# usb register map
Vendor: Texas Instruments
Peripheral module from a debugger description file (folder tm4c1232c3pm).
Registers are 8-bit, read-write, no defined reset value unless marked. A register's access mark holds for its fields unless they carry their own. Offsets are as the file gives them; lines under a group give offsets from that group; [hi:lo] are bit positions; {n}, {i} and the like mark numbered series; 'fields as' and 'values as' point back to an identical list; <NAME> marks a mode.

## USB0 — Univeral Serial Bus register offsets
0x00 USB_FADDR — USB Device Functional Address
  [6:0] USB_FADDR — Function Address
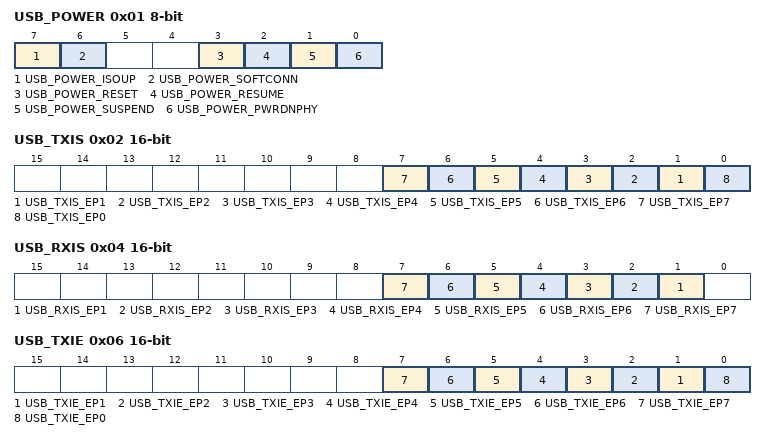
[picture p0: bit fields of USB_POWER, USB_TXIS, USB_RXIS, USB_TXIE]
0x01 USB_POWER
  [7] USB_POWER_ISOUP — Isochronous Update
  [6] USB_POWER_SOFTCONN — Soft Connect/Disconnect
  [3] USB_POWER_RESET — RESET Signaling
  [2] USB_POWER_RESUME — RESUME Signaling
  [1] USB_POWER_SUSPEND — SUSPEND Mode
  [0] USB_POWER_PWRDNPHY — Power Down PHY
0x02 USB_TXIS 16-bit ro — USB Transmit Interrupt Status
  [n] USB_TXIS_EP{n} (n=1..7) — TX Endpoint {n} Interrupt
  [0] USB_TXIS_EP0 — TX and RX Endpoint 0 Interrupt
0x04 USB_RXIS 16-bit ro — USB Receive Interrupt Status
  [n] USB_RXIS_EP{n} (n=1..7) — RX Endpoint {n} Interrupt
0x06 USB_TXIE 16-bit — USB Transmit Interrupt Enable
  [n] USB_TXIE_EP{n} (n=1..7) — TX Endpoint {n} Interrupt Enable
  [0] USB_TXIE_EP0 — TX and RX Endpoint 0 Interrupt Enable
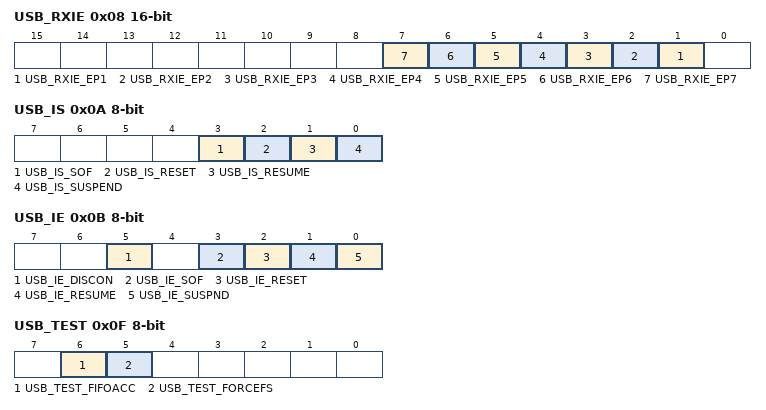
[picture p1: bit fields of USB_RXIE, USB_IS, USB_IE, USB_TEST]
0x08 USB_RXIE 16-bit — USB Receive Interrupt Enable
  [n] USB_RXIE_EP{n} (n=1..7) — RX Endpoint {n} Interrupt Enable
0x0A USB_IS ro — USB General Interrupt Status
  [3] USB_IS_SOF — Start of Frame
  [2] USB_IS_RESET — RESET Signaling Detected
  [1] USB_IS_RESUME — RESUME Signaling Detected
  [0] USB_IS_SUSPEND — SUSPEND Signaling Detected
0x0B USB_IE — USB Interrupt Enable
  [5] USB_IE_DISCON — Enable Disconnect Interrupt
  [3] USB_IE_SOF — Enable Start-of-Frame Interrupt
  [2] USB_IE_RESET — Enable RESET Interrupt
  [1] USB_IE_RESUME — Enable RESUME Interrupt
  [0] USB_IE_SUSPND — Enable SUSPEND Interrupt
0x0C USB_FRAME 16-bit ro — USB Frame Value
  [10:0] USB_FRAME — Frame Number
0x0E USB_EPIDX — USB Endpoint Index
  [3:0] USB_EPIDX_EPIDX — Endpoint Index
0x0F USB_TEST — USB Test Mode
  [6] USB_TEST_FIFOACC — FIFO Access
  [5] USB_TEST_FORCEFS — Force Full-Speed Mode
{0x20+4i} USB_FIFO{i} 32-bit (i=0..7) — USB FIFO Endpoint {i}
  [31:0] USB_FIFO{i}_EPDATA — Endpoint Data
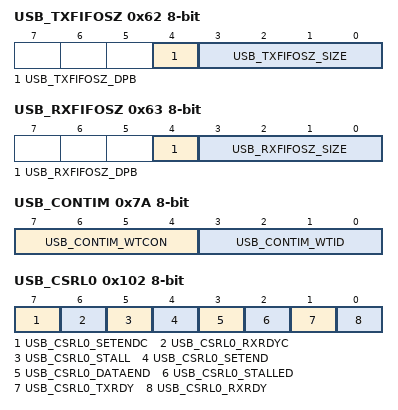
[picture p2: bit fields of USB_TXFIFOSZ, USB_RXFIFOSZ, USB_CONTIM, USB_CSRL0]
0x62 USB_TXFIFOSZ — USB Transmit Dynamic FIFO Sizing
  [4] USB_TXFIFOSZ_DPB — Double Packet Buffer Support
  [3:0] USB_TXFIFOSZ_SIZE — Max Packet Size
    0=8; 1=16; 2=32; 3=64; 4=128; 5=256; 6=512; 7=1024; 8=2048
0x63 USB_RXFIFOSZ — USB Receive Dynamic FIFO Sizing
  [4] USB_RXFIFOSZ_DPB — Double Packet Buffer Support
  [3:0] USB_RXFIFOSZ_SIZE — Max Packet Size
    0=8; 1=16; 2=32; 3=64; 4=128; 5=256; 6=512; 7=1024; 8=2048
0x64 USB_TXFIFOADD 16-bit — USB Transmit FIFO Start Address
  [8:0] USB_TXFIFOADD_ADDR — Transmit/Receive Start Address
0x66 USB_RXFIFOADD 16-bit — USB Receive FIFO Start Address
  [8:0] USB_RXFIFOADD_ADDR — Transmit/Receive Start Address
0x7A USB_CONTIM — USB Connect Timing
  [7:4] USB_CONTIM_WTCON — Connect Wait
  [3:0] USB_CONTIM_WTID — Wait ID
0x7D USB_FSEOF — USB Full-Speed Last Transaction to End of Frame Timing
  [7:0] USB_FSEOF_FSEOFG — Full-Speed End-of-Frame Gap
0x7E USB_LSEOF — USB Low-Speed Last Transaction to End of Frame Timing
  [7:0] USB_LSEOF_LSEOFG — Low-Speed End-of-Frame Gap
0x102 USB_CSRL0 wo — USB Control and Status Endpoint 0 Low
  [7] USB_CSRL0_SETENDC — Setup End Clear
  [6] USB_CSRL0_RXRDYC — RXRDY Clear
  [5] USB_CSRL0_STALL — Send Stall
  [4] USB_CSRL0_SETEND — Setup End
  [3] USB_CSRL0_DATAEND — Data End
  [2] USB_CSRL0_STALLED — Endpoint Stalled
  [1] USB_CSRL0_TXRDY — Transmit Packet Ready
  [0] USB_CSRL0_RXRDY — Receive Packet Ready
0x103 USB_CSRH0 wo — USB Control and Status Endpoint 0 High
  [0] USB_CSRH0_FLUSH — Flush FIFO
0x108 USB_COUNT0 ro — USB Receive Byte Count Endpoint 0
  [6:0] USB_COUNT0_COUNT — FIFO Count
{0x100+0x10*i} USB_TXMAXP{i} 16-bit (i=1..7) — USB Maximum Transmit Data Endpoint {i}
  [10:0] USB_TXMAXP{i}_MAXLOAD — Maximum Payload
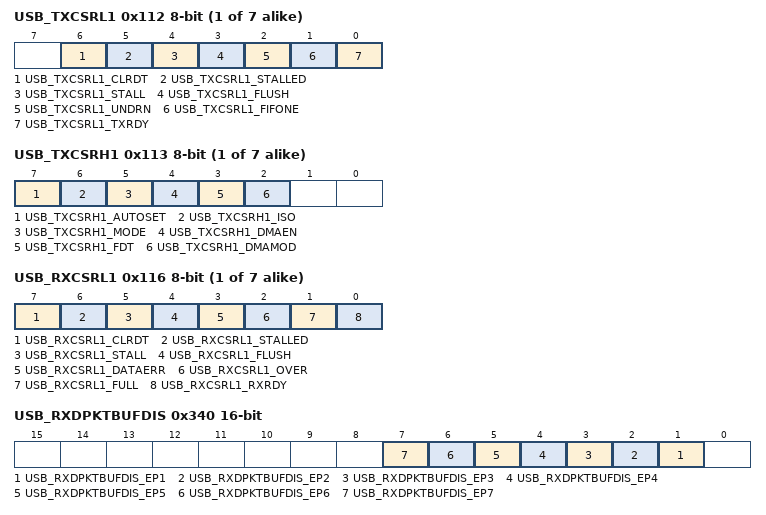
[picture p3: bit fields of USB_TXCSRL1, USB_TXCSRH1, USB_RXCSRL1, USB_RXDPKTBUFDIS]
{0x102+0x10*i} USB_TXCSRL{i} (i=1..7) — USB Transmit Control and Status Endpoint {i} Low
  [6] USB_TXCSRL{i}_CLRDT — Clear Data Toggle
  [5] USB_TXCSRL{i}_STALLED — Endpoint Stalled
  [4] USB_TXCSRL{i}_STALL — Send STALL
  [3] USB_TXCSRL{i}_FLUSH — Flush FIFO
  [2] USB_TXCSRL{i}_UNDRN — Underrun
  [1] USB_TXCSRL{i}_FIFONE — FIFO Not Empty
  [0] USB_TXCSRL{i}_TXRDY — Transmit Packet Ready
{0x103+0x10*i} USB_TXCSRH{i} (i=1..7) — USB Transmit Control and Status Endpoint {i} High
  [7] USB_TXCSRH{i}_AUTOSET — Auto Set
  [6] USB_TXCSRH{i}_ISO — Isochronous Transfers
  [5] USB_TXCSRH{i}_MODE — Mode
  [4] USB_TXCSRH{i}_DMAEN — DMA Request Enable
  [3] USB_TXCSRH{i}_FDT — Force Data Toggle
  [2] USB_TXCSRH{i}_DMAMOD — DMA Request Mode
{0x104+0x10*i} USB_RXMAXP{i} 16-bit (i=1..7) — USB Maximum Receive Data Endpoint {i}
  [10:0] USB_RXMAXP{i}_MAXLOAD — Maximum Payload
{0x106+0x10*i} USB_RXCSRL{i} (i=1..7) — USB Receive Control and Status Endpoint {i} Low
  [7] USB_RXCSRL{i}_CLRDT — Clear Data Toggle
  [6] USB_RXCSRL{i}_STALLED — Endpoint Stalled
  [5] USB_RXCSRL{i}_STALL — Send STALL
  [4] USB_RXCSRL{i}_FLUSH — Flush FIFO
  [3] USB_RXCSRL{i}_DATAERR — Data Error
  [2] USB_RXCSRL{i}_OVER — Overrun
  [1] USB_RXCSRL{i}_FULL — FIFO Full
  [0] USB_RXCSRL{i}_RXRDY — Receive Packet Ready
{0x107+0x10*i} USB_RXCSRH{i} (i=1..6) — USB Receive Control and Status Endpoint {i} High
  [7] USB_RXCSRH{i}_AUTOCL — Auto Clear
  [6] USB_RXCSRH{i}_ISO — Isochronous Transfers
  [5] USB_RXCSRH{i}_DMAEN — DMA Request Enable
  [4] USB_RXCSRH{i}_DISNYET — Disable NYET
  [4] USB_RXCSRH{i}_PIDERR — PID Error
  [3] USB_RXCSRH{i}_DMAMOD — DMA Request Mode
{0x108+0x10*i} USB_RXCOUNT{i} 16-bit ro (i=1..7) — USB Receive Byte Count Endpoint {i}
  [12:0] USB_RXCOUNT{i}_COUNT — Receive Packet Count
0x177 USB_RXCSRH7 — USB Receive Control and Status Endpoint 7 High
  [7] USB_RXCSRH7_AUTOCL — Auto Clear
  [6] USB_RXCSRH7_ISO — Isochronous Transfers
  [5] USB_RXCSRH7_DMAEN — DMA Request Enable
  [4] USB_RXCSRH7_PIDERR — PID Error
  [4] USB_RXCSRH7_DISNYET — Disable NYET
  [3] USB_RXCSRH7_DMAMOD — DMA Request Mode
0x340 USB_RXDPKTBUFDIS 16-bit — USB Receive Double Packet Buffer Disable
  [n] USB_RXDPKTBUFDIS_EP{n} (n=1..7) — EP{n} RX Double-Packet Buffer Disable
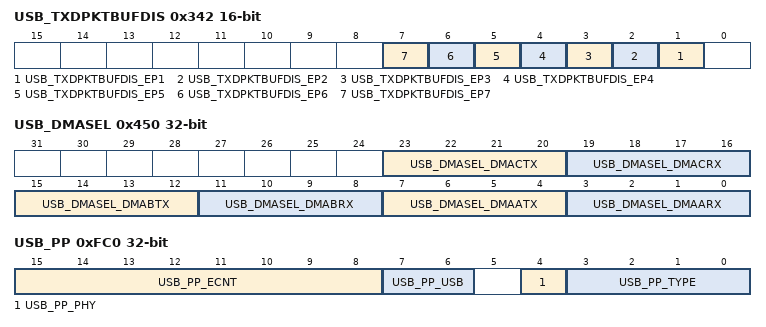
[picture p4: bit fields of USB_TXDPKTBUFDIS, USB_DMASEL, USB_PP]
0x342 USB_TXDPKTBUFDIS 16-bit — USB Transmit Double Packet Buffer Disable
  [n] USB_TXDPKTBUFDIS_EP{n} (n=1..7) — EP{n} TX Double-Packet Buffer Disable
0x410 USB_DRRIS 32-bit ro — USB Device RESUME Raw Interrupt Status
  [0] USB_DRRIS_RESUME — RESUME Interrupt Status
0x414 USB_DRIM 32-bit — USB Device RESUME Interrupt Mask
  [0] USB_DRIM_RESUME — RESUME Interrupt Mask
0x418 USB_DRISC 32-bit wo — USB Device RESUME Interrupt Status and Clear
  [0] USB_DRISC_RESUME — RESUME Interrupt Status and Clear
0x450 USB_DMASEL 32-bit — USB DMA Select
  [23:20] USB_DMASEL_DMACTX — DMA C TX Select
  [19:16] USB_DMASEL_DMACRX — DMA C RX Select
  [15:12] USB_DMASEL_DMABTX — DMA B TX Select
  [11:8] USB_DMASEL_DMABRX — DMA B RX Select
  [7:4] USB_DMASEL_DMAATX — DMA A TX Select
  [3:0] USB_DMASEL_DMAARX — DMA A RX Select
0xFC0 USB_PP 32-bit ro — USB Peripheral Properties
  [15:8] USB_PP_ECNT — Endpoint Count
  [7:6] USB_PP_USB — USB Capability
    1=USB_PP_USB_DEVICE (DEVICE); 2=USB_PP_USB_HOSTDEVICE (HOST); 3=USB_PP_USB_OTG (OTG)
  [4] USB_PP_PHY — PHY Present
  [3:0] USB_PP_TYPE — Controller Type
    0=The first-generation USB controller
